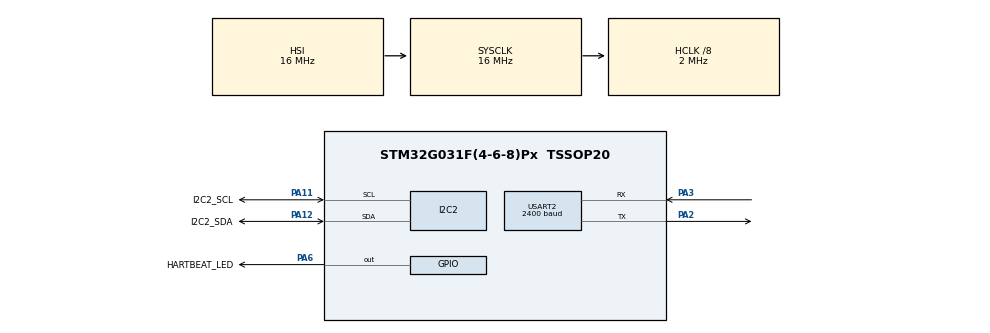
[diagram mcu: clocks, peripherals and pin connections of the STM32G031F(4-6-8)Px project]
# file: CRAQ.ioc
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I2C2.Timing=0x00000509
Mcu.Family=STM32G0
Mcu.Name=STM32G031F(4-6-8)Px
Mcu.Package=TSSOP20
PA11\ [PA9].GPIO_Label=I2C2_SCL
PA11\ [PA9].GPIO_Pu=GPIO_PULLUP
PA11\ [PA9].Mode=I2C
PA11\ [PA9].Signal=I2C2_SCL
PA12\ [PA10].GPIO_Label=I2C2_SDA
PA12\ [PA10].GPIO_Pu=GPIO_PULLUP
PA12\ [PA10].Mode=I2C
PA12\ [PA10].Signal=I2C2_SDA
PA13.Mode=Serial_Wire
PA13.Signal=SYS_SWDIO
PA14-BOOT0.Mode=Serial_Wire
PA14-BOOT0.Signal=SYS_SWCLK
PA2.Mode=Asynchronous
PA2.Signal=USART2_TX
PA3.Mode=Asynchronous
PA3.Signal=USART2_RX
PA6.GPIO_Label=HARTBEAT_LED
PA6.Signal=GPIO_Output
ProjectManager.HeapSize=0x200
ProjectManager.StackSize=0x600
ProjectManager.TargetToolchain=STM32CubeIDE
RCC.AHBCLKDivider=RCC_SYSCLK_DIV8
RCC.AHBFreq_Value=2000000
RCC.CortexFreq_Value=2000000
RCC.EXTERNAL_CLOCK_VALUE=12288000
RCC.HCLKFreq_Value=2000000
RCC.HSE_VALUE=8000000
RCC.HSI_VALUE=16000000
RCC.LSE_VALUE=32768
RCC.SYSCLKFreq_VALUE=16000000
RCC.VCOOutputFreq_Value=128000000
USART2.BaudRate=2400
USART2.Parity=PARITY_EVEN
USART2.VirtualMode-Asynchronous=VM_ASYNC
USART2.WordLength=WORDLENGTH_9B
board=custom

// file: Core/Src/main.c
/* USER CODE BEGIN Header */
/**
 ******************************************************************************
 * @file           : main.c
 * @brief          : Main program body
 ******************************************************************************
 * @attention
 *
 * <h2><center>&copy; Copyright (c) 2021 STMicroelectronics.
 * All rights reserved.</center></h2>
 *
 * This software component is licensed by ST under BSD 3-Clause license,
 * the "License"; You may not use this file except in compliance with the
 * License. You may obtain a copy of the License at:
 *                        opensource.org/licenses/BSD-3-Clause
 *
 ******************************************************************************
 */
/* USER CODE END Header */
#include "main.h"
#include "i2c.h"
#include "usart.h"
#include "gpio.h"
#include "ccs811.h"

void SystemClock_Config(void);

int main(void) {

	/* MCU Configuration--------------------------------------------------------*/

	/* Reset of all peripherals, Initializes the Flash interface and the Systick. */
	HAL_Init();

	/* Configure the system clock */
	SystemClock_Config();

	/* Initialize all configured peripherals */
	MX_GPIO_Init();
	MX_I2C2_Init();
	MX_USART2_UART_Init();

	/* Infinite loop */
	/* USER CODE BEGIN WHILE */
	ccs811_init();

	while (1) {
		ccs811_measureCO2();
		/* USER CODE END WHILE */

	}
}

void SystemClock_Config(void) {
	RCC_OscInitTypeDef RCC_OscInitStruct = { 0 };
	RCC_ClkInitTypeDef RCC_ClkInitStruct = { 0 };

	/** Configure the main internal regulator output voltage
	 */
	HAL_PWREx_ControlVoltageScaling(PWR_REGULATOR_VOLTAGE_SCALE1);
	/** Initializes the RCC Oscillators according to the specified parameters
	 * in the RCC_OscInitTypeDef structure.
	 */
	RCC_OscInitStruct.OscillatorType = RCC_OSCILLATORTYPE_HSI;
	RCC_OscInitStruct.HSIState = RCC_HSI_ON;
	RCC_OscInitStruct.HSIDiv = RCC_HSI_DIV1;
	RCC_OscInitStruct.HSICalibrationValue = RCC_HSICALIBRATION_DEFAULT;
	RCC_OscInitStruct.PLL.PLLState = RCC_PLL_NONE;
	if (HAL_RCC_OscConfig(&RCC_OscInitStruct) != HAL_OK) {
		Error_Handler();
	}
	/** Initializes the CPU, AHB and APB buses clocks
	 */
	RCC_ClkInitStruct.ClockType = RCC_CLOCKTYPE_HCLK | RCC_CLOCKTYPE_SYSCLK
			| RCC_CLOCKTYPE_PCLK1;
	RCC_ClkInitStruct.SYSCLKSource = RCC_SYSCLKSOURCE_HSI;
	RCC_ClkInitStruct.AHBCLKDivider = RCC_SYSCLK_DIV8;
	RCC_ClkInitStruct.APB1CLKDivider = RCC_HCLK_DIV1;

	if (HAL_RCC_ClockConfig(&RCC_ClkInitStruct, FLASH_LATENCY_0) != HAL_OK) {
		Error_Handler();
	}
}

void Error_Handler(void) {
	__disable_irq();
	while (1) {
	}
}

/************************ (C) COPYRIGHT STMicroelectronics *****END OF FILE****/
